# CM_MPU register map
Vendor: Texas Instruments
Peripheral module from a debugger description file (folder am335x).
Registers are 32-bit, access per field, no defined reset value unless marked. A register's access mark holds for its fields unless they carry their own. Offsets are as the file gives them; lines under a group give offsets from that group; [hi:lo] are bit positions; {n}, {i} and the like mark numbered series; 'fields as' and 'values as' point back to an identical list; <NAME> marks a mode.

## CM_MPU
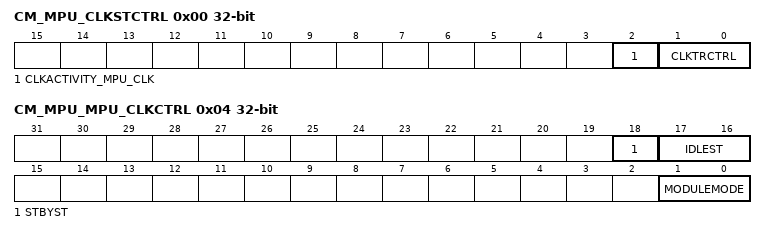
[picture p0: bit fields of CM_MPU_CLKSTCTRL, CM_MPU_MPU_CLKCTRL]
0x00 CM_MPU_CLKSTCTRL — This register enables the domain power state transition. It controls the SW supervised clock domain state transition between ON-ACTIVE and ON-INACTIVE states. It also hold one status bit per clock input of the domain.
  [2] CLKACTIVITY_MPU_CLK ro — This field indicates the state of the MPU Clock
    0=Inact (Corresponding clock is gated); 1=Act (Corresponding clock is active)
  [1:0] CLKTRCTRL rw — Controls the clock state transition of the MPU clock domains.
    0=NO_SLEEP (NO_SLEEP: Sleep transition cannot be initiated. Wakeup transition may however occur.); 1=SW_SLEEP (SW_SLEEP: Start a software forced sleep transition on the domain.); 2=SW_WKUP (SW_WKUP: Start a software forced wake-up transition on the domain.)
0x04 CM_MPU_MPU_CLKCTRL — This register manages the MPU clocks.
  [18] STBYST ro — Module standby status.
    0=Func (Module is functional (not in standby)); 1=Standby (Module is in standby)
  [17:16] IDLEST ro — Module idle status.
    0=Func (Module is fully functional, including OCP); 1=Trans (Module is performing transition: wakeup, or sleep, or sleep abortion); 2=Idle (Module is in Idle mode (only OCP part). It is functional if using separate functional clock); 3=Disable (Module is disabled and cannot be accessed)
  [1:0] MODULEMODE rw — Control the way mandatory clocks are managed.
    0=DISABLED (Module is disable by SW. Any OCP access to module results in an error, except if resulting from a module wakeup (asynchronous wakeup).); 2=ENABLE (Module is explicitly enabled. Interface clock (if not used for functions) may be gated according to the clock domain state. Functional clocks are guarantied to stay present. As long as in this configuration, power domain sleep transition cannot happen.)
